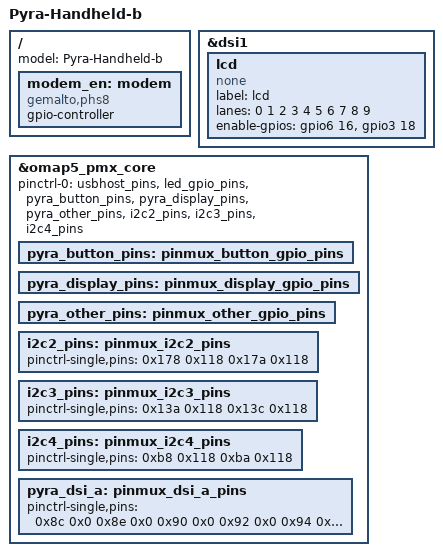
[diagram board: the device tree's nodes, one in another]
/*
 * Copyright (C) 2014 OpenPandora - http://www.pyra-handheld.com/
 *
 * This program is free software; you can redistribute it and/or modify
 * it under the terms of the GNU General Public License version 2 as
 * published by the Free Software Foundation.
 */

/* we start with the omap5-uevm tree */

#include "omap5-uevm.dts"

/* overwrite device model */

/ {
	model = "Pyra-Handheld-b";

/*	aliases { */

	modem_en: modem { /* control modem power through rfkill */
		compatible = "gemalto,phs8";
		gpio-controller;
		#gpio-cells = <2>;

	/*	usb-port = <&hsusb2_phy>; */
	/* FIXME:	on-off-gpio = <&gpio6 26 0>;	/* GPIO_186: trigger to power on modem */
	/*	on-indicator-gpio = <&gpio5 19 0>;	/* Feedback GPIO */
	};
};

/* LCD panel - MIPI */

/*&dss {
};*/

&dsi1 {
	// status = "ok";
	// vdd-supply = ???

	// pinctrl-names

	// port {
		// lcd: endpoint
	lcd {
		compatible = "none";	/* default to be overwritten by specific panel */
		label = "lcd";
		lanes = <
			0       /* lane0+ = clk + */
			1       /* lane0- = clk - */
			2       /* lane1+ = data1 + */
			3       /* lane1- = data1 - */
			4       /* lane2+ = data2 + */
			5       /* lane2- = data2 - */
			6       /* lane3+ = data3 + */
			7       /* lane3- = data3 - */
			8       /* lane4+ = data4 + */
			9       /* lane4- = data4 - */
		>;

		enable-gpios =
			<&gpio6 16 0>,	/* goip6_176 = display reset */
			<&gpio3 18 0>;	/* gpio3_82 = enable DC/DC */
	};
	// }; port
};

/* add overlay pimmux for pyra on 5432evm */

&omap5_pmx_core {

	pinctrl-0 = <
			/* copied from original */
			&usbhost_pins
			&led_gpio_pins

			/* new entries */
			&pyra_button_pins
			&pyra_display_pins
			&pyra_other_pins
			&i2c2_pins
			&i2c3_pins
			&i2c4_pins
	>;
/*
// inputs
#define GPIO_AUX 83			// BTN1 on EVM motherboard (gpio3_83)
#define GPIO_VSYNC 189			// VSYNC input (gpio6_189 in: comes from panel)
#define GPIO_LSH_TOP 184		// left top shoulder button - gpio6-184 - closes to GND
#define GPIO_LSH_BOT 183		// left bottom shoulder button - gpio6-183 - closes to GND
#define GPIO_RSH_TOP 180		// right top shoulder button - gpio6-180 - closes to GND
#define GPIO_RSH_BOT 179		// right bottom shoulder button - gpio6-179 - closes to GND
#define GPIO_LNUB 182			// left nub center button - gpio6-182 - closes to GND
#define GPIO_RNUB 181			// right nub center button - gpio6-181 - closes to GND
#define GPIO_LNUB_IRQ -1		// left nub IRQ - n/a
#define GPIO_RNUB_IRQ -1		// right nub IRQ - n/a
#define GPIO_LID 160			// lid close sensor - gpio6-160 - open collector output
#define GPIO_WAKEUP 161			// wakeup from modem - gpio6-161
#define GPIO_KEYIRQ 177			// keyboard controller IRQ - gpio6-177
#define GPIO_PENIRQ 173			// touch screen controller IRQ - gpio6-173
// outputs
#define GPIO_DISPEN 82			// enable (active high) +/-5 V TPS65133 - gpio3_82
#define GPIO_PWM 190			// enable 18V backlight (active high) - timer9/gpio6_190 (out) - or input to track what the panel is doing
#define GPIO_DISPLAY_RESET 176		// panel reset (active low)/enable - gpio6_176
#define GPIO_PERIPHERAL_RESET 230	// device reset (active low)/enable - gpio8_230
#define GPIO_3G_IGNITE 178		// start modem (active high pulse) - gpio6-178
*/

/* to find pinmux register offsets, see section A.7.2 in TRM

   note: offsets in the table are relative to 0x4a00 2800
   but reg = <0x4a002840 0x01b6> for omap5_pmx_core

   Therefore gpio5_153 with Address Offset 0x1D4
   translates into 0x194 (0xd0-0x40 => 0x90)
   and because it has [31:16] we have to add 0x02
   giving a result of 0x196.

   Definitions for bit patterns:
   0x0007	MUX_MODE0 .. MUX_MODE7
   0x0008	enable pull up/down
   0x0010	select pull up
   0x0020	disable power for I/O cell
   0x0100	enable input buffer (there is no explicit "enable output buffer" because that is defined by the GPIO direction)
   0x4000	enable wakeup detection
*/

	pyra_button_pins: pinmux_button_gpio_pins {
//		pinctrl-single,pins = <
//			0x76 0x11e	/* (PIN_INPUT_PULLUP | MUX_MODE6)	/* 0x0B4:[31:16] gpio3_83  -- pullup is not really necessary since there is an external pullup */
//			0xec 0x11e	/* (PIN_INPUT_PULLUP | MUX_MODE6)	/* 0x12C:[15:0]  gpio6_160 */
//			0xee 0x11e	/* (PIN_INPUT_PULLUP | MUX_MODE6)	/* 0x12C:[31:16] gpio6_161 */
//			0xcc 0x11e	/* (PIN_INPUT_PULLUP | MUX_MODE6)	/* 0x10C:[15:0]  gpio6_177 */
//			0xc8 0x11e	/* (PIN_INPUT_PULLUP | MUX_MODE6)	/* 0x108:[15:0]  gpio6_179 */
//			0xc6 0x11e	/* (PIN_INPUT_PULLUP | MUX_MODE6)	/* 0x104:[31:16] gpio6_180 */
//			0xc4 0x11e	/* (PIN_INPUT_PULLUP | MUX_MODE6)	/* 0x104:[15:0]  gpio6_181 */
//			0xf0 0x11e	/* (PIN_INPUT_PULLUP | MUX_MODE6)	/* 0x130:[15:0]  gpio6_182 */
//			0xf2 0x11e	/* (PIN_INPUT_PULLUP | MUX_MODE6)	/* 0x130:[31:16] gpio6_183 */
//			0xf4 0x11e	/* (PIN_INPUT_PULLUP | MUX_MODE6)	/* 0x134:[15:0]  gpio6_184 */
//		>;
	};

	pyra_display_pins: pinmux_display_gpio_pins {
//		pinctrl-single,pins = <
//			0x74 0x00e	/* (PIN_OUTPUT_PULLDOWN | MUX_MODE6)	/* 0x0B4:[15:0]  gpio3_82 - enable panel DC/DC */
//			0x8a 0x10f	/* (PIN_INPUT_PULLDOWN | MUX_MODE6)	/* 0x0C8:[31:16] gpio6_189 - VSYNC input */
//			0xb6 0x10f	/* (PIN_INPUT_PULLDOWN | MUX_MODE7)	/* 0x0F4:[31:16] gpio6_190 - choose MUX_MODE0 for PWM_TIMER9 - choose MUX_MODE7 if panel outputs the PWM */
//			0xce 0x00e	/* (PIN_OUTPUT_PULLDOWN | MUX_MODE6)	/* 0x178:[31:16] gpio6_176 - panel reset */
//		>;
	};

	pyra_other_pins: pinmux_other_gpio_pins {
//		pinctrl-single,pins = <
//			0xca 0x00e	/* (PIN_OUTPUT_PULLDOWN | MUX_MODE6)		/* 0x108:[31:16] gpio6_178 - start modem */
//			0xd4 0x11e	/* (PIN_INPUT_PULLUP | MUX_MODE6)	/* 0x114:[15:0] gpio6_173 - touch screen */
//			0x138 0x11e	/* (PIN_INPUT_PULLUP | MUX_MODE6)	/* 0x178:[15:0]  gpio8_230 - reset I2C peripherals */
//		>;
	};

/* enable I2C pinmux */

	i2c2_pins: pinmux_i2c2_pins {
		pinctrl-single,pins = <
			0x178 0x118	/* (PIN_INPUT_PULLUP | MUX_MUX_MODE0)		/* i2c2_scl */
			0x17a 0x118	/* (PIN_INPUT_PULLUP | MUX_MUX_MODE0)		/* i2c2_sda */
		>;
	};

	i2c3_pins: pinmux_i2c3_pins {
		pinctrl-single,pins = <
			0x13a 0x118	/* (PIN_INPUT_PULLUP | MUX_MUX_MODE0)		/* i2c3_scl */
			0x13c 0x118	/* (PIN_INPUT_PULLUP | MUX_MUX_MODE0)		/* i2c3_sda */
		>;
	};

	i2c4_pins: pinmux_i2c4_pins {
		pinctrl-single,pins = <
			0xb8 0x118	/* (PIN_INPUT_PULLUP | MUX_MUX_MODE0)		/* i2c4_scl (gpio7_200) */
			0xba 0x118	/* (PIN_INPUT_PULLUP | MUX_MUX_MODE0)		/* i2c4_sda (gpio7_201) */
		>;
	};

/* enable MIPI pinmux - we may not really need this because the PinMux only has MUX_MODE0 */

	pyra_dsi_a: pinmux_dsi_a_pins {
		pinctrl-single,pins = <
			0x8c 0x0	/* (PIN_OUTPUT | MUX_MODE0)	/* 0x0cc:[15:0]  dsiporta_lane0x */
			0x8e 0x0	/* (PIN_OUTPUT | MUX_MODE0)	/* 0x0cc:[31:16] dsiporta_lane0y */
			0x90 0x0	/* (PIN_OUTPUT | MUX_MODE0)	/* 0x0d0:[15:0]  dsiporta_lane1x */
			0x92 0x0	/* (PIN_OUTPUT | MUX_MODE0)	/* 0x0d0:[31:16] dsiporta_lane1y */
			0x94 0x0	/* (PIN_OUTPUT | MUX_MODE0)	/* 0x0d4:[15:0]  dsiporta_lane2x */
			0x96 0x0	/* (PIN_OUTPUT | MUX_MODE0)	/* 0x0d4:[31:16] dsiporta_lane2y */
			0x98 0x0	/* (PIN_OUTPUT | MUX_MODE0)	/* 0x0d8:[15:0]  dsiporta_lane3x */
			0x9a 0x0	/* (PIN_OUTPUT | MUX_MODE0)	/* 0x0d8:[31:16] dsiporta_lane3y */
			0x9c 0x0	/* (PIN_OUTPUT | MUX_MODE0)	/* 0x0dc:[15:0]  dsiporta_lane4x */
			0x9e 0x0	/* (PIN_OUTPUT | MUX_MODE0)	/* 0x0dc:[31:16] dsiporta_lane4y */
		>;
	};
};

/* more things to do:
* add a regulator-gpio for the LCD
* configure WLAN/Bluetooth module
*/
